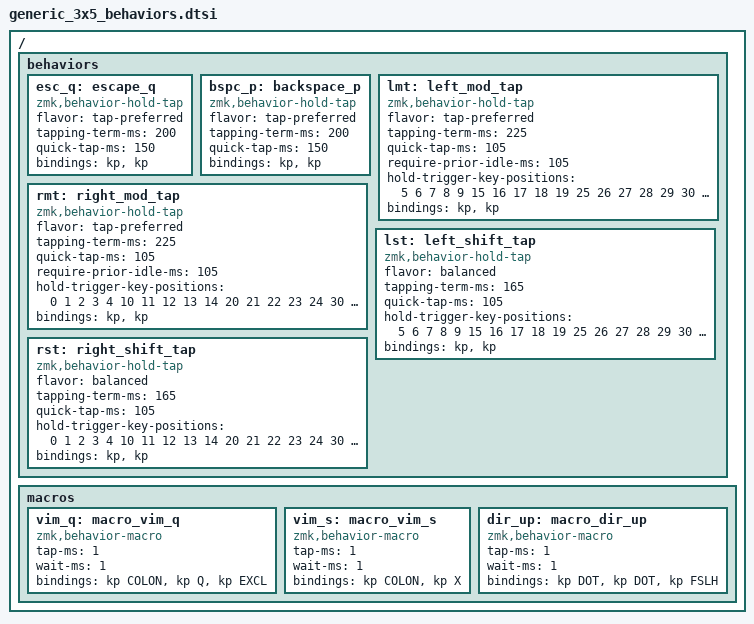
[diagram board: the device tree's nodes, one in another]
/*
 * Generic 3x5 Behaviors and Macros
 * 
 * Shared behaviors and macros used by generic_3x5_layers.dtsi
 * Include this file in your board keymap before including the layers
 */

/ {
    behaviors {
        esc_q: escape_q {
            compatible = "zmk,behavior-hold-tap";
            #binding-cells = <2>;
            flavor = "tap-preferred";
            tapping-term-ms = <200>;
            quick-tap-ms = <150>;
            bindings = <&kp>, <&kp>;
        };

        bspc_p: backspace_p {
            compatible = "zmk,behavior-hold-tap";
            #binding-cells = <2>;
            flavor = "tap-preferred";
            tapping-term-ms = <200>;
            quick-tap-ms = <150>;
            bindings = <&kp>, <&kp>;
        };

        // Homerow mods - Left hand
        lmt: left_mod_tap {
            compatible = "zmk,behavior-hold-tap";
            #binding-cells = <2>;
            flavor = "tap-preferred";
            tapping-term-ms = <225>;
            quick-tap-ms = <105>;
            require-prior-idle-ms = <105>;
            hold-trigger-key-positions = <5 6 7 8 9 15 16 17 18 19 25 26 27 28 29 30 31 32 33>;
            bindings = <&kp>, <&kp>;
        };

        // Homerow mods - Right hand
        rmt: right_mod_tap {
            compatible = "zmk,behavior-hold-tap";
            #binding-cells = <2>;
            flavor = "tap-preferred";
            tapping-term-ms = <225>;
            quick-tap-ms = <105>;
            require-prior-idle-ms = <105>;
            hold-trigger-key-positions = <0 1 2 3 4 10 11 12 13 14 20 21 22 23 24 30 31 32 33>;
            bindings = <&kp>, <&kp>;
        };

        // Homerow mods - Left Shift
        lst: left_shift_tap {
            compatible = "zmk,behavior-hold-tap";
            #binding-cells = <2>;
            flavor = "balanced";
            tapping-term-ms = <165>;
            quick-tap-ms = <105>;
            hold-trigger-key-positions = <5 6 7 8 9 15 16 17 18 19 25 26 27 28 29 30 31 32 33>;
            bindings = <&kp>, <&kp>;
        };

        // Homerow mods - Right Shift
        rst: right_shift_tap {
            compatible = "zmk,behavior-hold-tap";
            #binding-cells = <2>;
            flavor = "balanced";
            tapping-term-ms = <165>;
            quick-tap-ms = <105>;
            hold-trigger-key-positions = <0 1 2 3 4 10 11 12 13 14 20 21 22 23 24 30 31 32 33>;
            bindings = <&kp>, <&kp>;
        };
    };

    macros {
        vim_q: macro_vim_q {
            compatible = "zmk,behavior-macro";
            #binding-cells = <0>;
            tap-ms = <1>;
            wait-ms = <1>;
            bindings = <&kp COLON &kp Q &kp EXCL>;
        };

        vim_s: macro_vim_s {
            compatible = "zmk,behavior-macro";
            #binding-cells = <0>;
            tap-ms = <1>;
            wait-ms = <1>;
            bindings = <&kp COLON &kp X>;
        };

        dir_up: macro_dir_up {
            compatible = "zmk,behavior-macro";
            #binding-cells = <0>;
            tap-ms = <1>;
            wait-ms = <1>;
            bindings = <&kp DOT &kp DOT &kp FSLH>;
        };
    };
};
